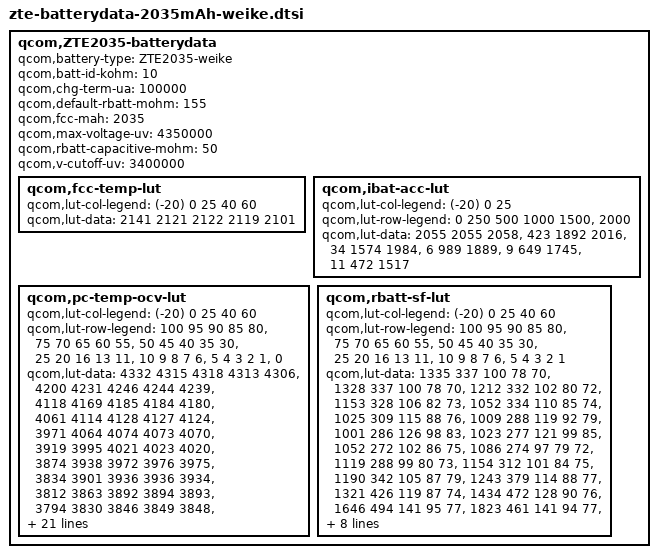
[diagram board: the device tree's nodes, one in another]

qcom,ZTE2035-batterydata {
	qcom,battery-type = "ZTE2035-weike";
	qcom,batt-id-kohm = <10>;
	qcom,chg-term-ua = <100000>;
	qcom,default-rbatt-mohm = <155>;
	qcom,fcc-mah = <2035>;
	qcom,max-voltage-uv = <4350000>;
	qcom,rbatt-capacitive-mohm = <50>;
	qcom,v-cutoff-uv = <3400000>;

	qcom,fcc-temp-lut {
		qcom,lut-col-legend = <(-20) 0 25 40 60>;
		qcom,lut-data = <2141 2121 2122 2119 2101>;
	};

	qcom,ibat-acc-lut {
		qcom,lut-col-legend = <(-20) 0 25>;
		qcom,lut-row-legend = <0 250 500 1000 1500>,
					<2000>;
		qcom,lut-data = <2055 2055 2058>,
				<423 1892 2016>,
				<34 1574 1984>,
				<6 989 1889>,
				<9 649 1745>,
				<11 472 1517>;
	};

	qcom,pc-temp-ocv-lut {
		qcom,lut-col-legend = <(-20) 0 25 40 60>;
		qcom,lut-row-legend = <100 95 90 85 80>,
					<75 70 65 60 55>,
					<50 45 40 35 30>,
					<25 20 16 13 11>,
					<10 9 8 7 6>,
					<5 4 3 2 1>,
					<0>;
		qcom,lut-data = <4332 4315 4318 4313 4306>,
				<4200 4231 4246 4244 4239>,
				<4118 4169 4185 4184 4180>,
				<4061 4114 4128 4127 4124>,
				<3971 4064 4074 4073 4070>,
				<3919 3995 4021 4023 4020>,
				<3874 3938 3972 3976 3975>,
				<3834 3901 3936 3936 3934>,
				<3812 3863 3892 3894 3893>,
				<3794 3830 3846 3849 3848>,
				<3776 3805 3816 3817 3816>,
				<3756 3790 3796 3796 3795>,
				<3734 3780 3781 3781 3779>,
				<3710 3772 3774 3772 3769>,
				<3684 3763 3769 3763 3754>,
				<3658 3751 3758 3750 3735>,
				<3631 3730 3739 3731 3717>,
				<3605 3697 3714 3708 3696>,
				<3580 3652 3685 3682 3673>,
				<3558 3605 3654 3659 3657>,
				<3545 3582 3633 3641 3644>,
				<3531 3561 3607 3617 3623>,
				<3515 3542 3581 3592 3599>,
				<3497 3525 3560 3570 3576>,
				<3475 3509 3540 3549 3554>,
				<3448 3490 3518 3520 3525>,
				<3414 3455 3479 3472 3471>,
				<3368 3400 3411 3409 3408>,
				<3289 3317 3331 3332 3327>,
				<3180 3210 3222 3228 3214>,
				<3000 3000 3000 3000 3000>;
	};

	qcom,rbatt-sf-lut {
		qcom,lut-col-legend = <(-20) 0 25 40 60>;
		qcom,lut-row-legend = <100 95 90 85 80>,
					<75 70 65 60 55>,
					<50 45 40 35 30>,
					<25 20 16 13 11>,
					<10 9 8 7 6>,
					<5 4 3 2 1>;
		qcom,lut-data = <1335 337 100 78 70>,
				<1328 337 100 78 70>,
				<1212 332 102 80 72>,
				<1153 328 106 82 73>,
				<1052 334 110 85 74>,
				<1025 309 115 88 76>,
				<1009 288 119 92 79>,
				<1001 286 126 98 83>,
				<1023 277 121 99 85>,
				<1052 272 102 86 75>,
				<1086 274 97 79 72>,
				<1119 288 99 80 73>,
				<1154 312 101 84 75>,
				<1190 342 105 87 79>,
				<1243 379 114 88 77>,
				<1321 426 119 87 74>,
				<1434 472 128 90 76>,
				<1646 494 141 95 77>,
				<1823 461 141 94 77>,
				<2393 470 151 101 79>,
				<2845 484 155 104 80>,
				<3444 512 153 107 83>,
				<4344 562 152 108 85>,
				<5745 648 155 110 86>,
				<8083 786 162 112 86>,
				<12103 1005 170 109 85>,
				<19215 1438 174 108 83>,
				<32026 2400 195 113 85>,
				<60235 4548 245 122 90>,
				<105826 8263 359 137 97>;
	};
};
